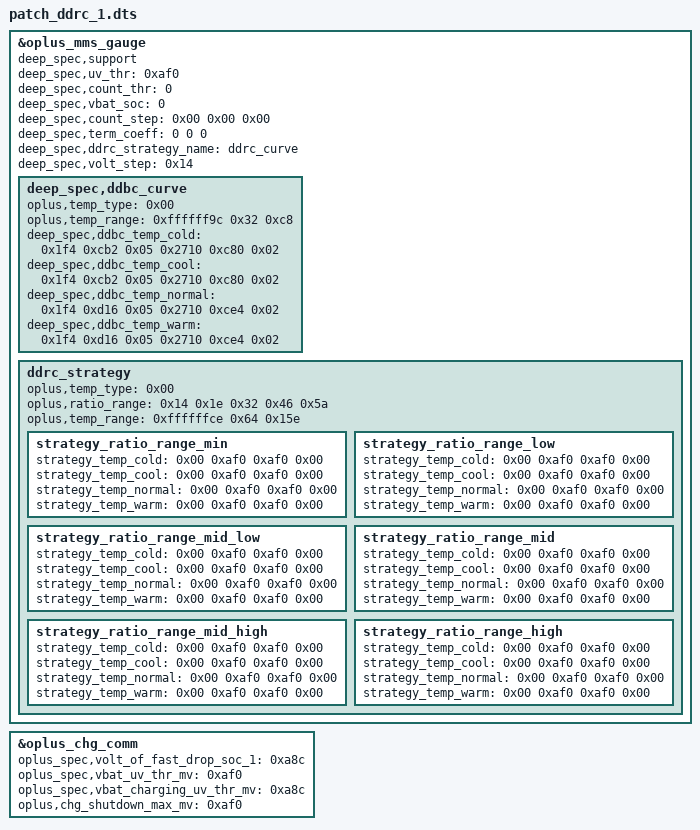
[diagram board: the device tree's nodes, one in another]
/dts-v1/;
/plugin/;

/ {
	fragment@0 {
		target = <&oplus_mms_gauge>;
		__overlay__ {
			deep_spec,support;
			deep_spec,uv_thr = <0xaf0>;
			deep_spec,count_thr = <0>;
			deep_spec,vbat_soc = <0>;
			deep_spec,count_step = <0x00 0x00 0x00>;
			deep_spec,term_coeff = <0 0 0>;
			deep_spec,ddrc_strategy_name = "ddrc_curve";
			deep_spec,volt_step = <0x14>;
			
			deep_spec,ddbc_curve {
				oplus,temp_type = <0x00>;
				oplus,temp_range = <0xffffff9c 0x32 0xc8>;
				deep_spec,ddbc_temp_cold = <0x1f4 0xcb2 0x05 0x2710 0xc80 0x02>;
				deep_spec,ddbc_temp_cool = <0x1f4 0xcb2 0x05 0x2710 0xc80 0x02>;
				deep_spec,ddbc_temp_normal = <0x1f4 0xd16 0x05 0x2710 0xce4 0x02>;
				deep_spec,ddbc_temp_warm = <0x1f4 0xd16 0x05 0x2710 0xce4 0x02>;
			};
			
			ddrc_strategy {
				oplus,temp_type = <0x00>;
				oplus,ratio_range = <0x14 0x1e 0x32 0x46 0x5a>;
				oplus,temp_range = <0xffffffce 0x64 0x15e>;
				
				strategy_ratio_range_min {
					strategy_temp_cold = <0x00 0xaf0 0xaf0 0x00>;
					strategy_temp_cool = <0x00 0xaf0 0xaf0 0x00>;
					strategy_temp_normal = <0x00 0xaf0 0xaf0 0x00>;
					strategy_temp_warm = <0x00 0xaf0 0xaf0 0x00>;
				};
				
				strategy_ratio_range_low {
					strategy_temp_cold = <0x00 0xaf0 0xaf0 0x00>;
					strategy_temp_cool = <0x00 0xaf0 0xaf0 0x00>;
					strategy_temp_normal = <0x00 0xaf0 0xaf0 0x00>;
					strategy_temp_warm = <0x00 0xaf0 0xaf0 0x00>;
				};
				
				strategy_ratio_range_mid_low {
					strategy_temp_cold = <0x00 0xaf0 0xaf0 0x00>;
					strategy_temp_cool = <0x00 0xaf0 0xaf0 0x00>;
					strategy_temp_normal = <0x00 0xaf0 0xaf0 0x00>;
					strategy_temp_warm = <0x00 0xaf0 0xaf0 0x00>;
				};
				
				strategy_ratio_range_mid {
					strategy_temp_cold = <0x00 0xaf0 0xaf0 0x00>;
					strategy_temp_cool = <0x00 0xaf0 0xaf0 0x00>;
					strategy_temp_normal = <0x00 0xaf0 0xaf0 0x00>;
					strategy_temp_warm = <0x00 0xaf0 0xaf0 0x00>;
				};
				
				strategy_ratio_range_mid_high {
					strategy_temp_cold = <0x00 0xaf0 0xaf0 0x00>;
					strategy_temp_cool = <0x00 0xaf0 0xaf0 0x00>;
					strategy_temp_normal = <0x00 0xaf0 0xaf0 0x00>;
					strategy_temp_warm = <0x00 0xaf0 0xaf0 0x00>;
				};
				
				strategy_ratio_range_high {
					strategy_temp_cold = <0x00 0xaf0 0xaf0 0x00>;
					strategy_temp_cool = <0x00 0xaf0 0xaf0 0x00>;
					strategy_temp_normal = <0x00 0xaf0 0xaf0 0x00>;
					strategy_temp_warm = <0x00 0xaf0 0xaf0 0x00>;
				};
			};
		};
	};
	
	fragment@1 {
		target = <&oplus_chg_comm>;
		__overlay__ {
			oplus_spec,volt_of_fast_drop_soc_1 = <0xa8c>;
			oplus_spec,vbat_uv_thr_mv = <0xaf0>;
			oplus_spec,vbat_charging_uv_thr_mv = <0xa8c>;
			oplus,chg_shutdown_max_mv = <0xaf0>;
		};
	};
};
